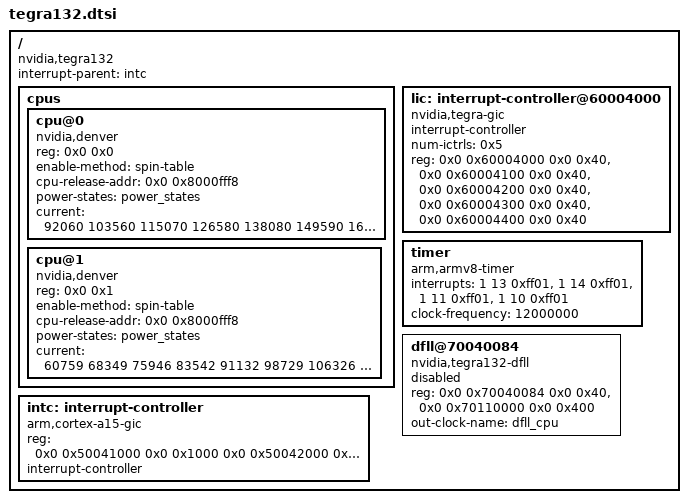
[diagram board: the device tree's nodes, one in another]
#include <dt-bindings/gpio/tegra-gpio.h>
#include <dt-bindings/input/input.h>
#include <dt-bindings/interrupt-controller/arm-gic.h>

/include/ "denver.dtsi"
/include/ "tegra124-soc.dtsi"

/ {
	compatible = "nvidia,tegra132";
	interrupt-parent = <&intc>;
	#address-cells = <2>;
	#size-cells = <2>;

	cpus {
		#address-cells = <2>;
		#size-cells = <0>;

		cpu@0 {
			device_type = "cpu";
			compatible = "nvidia,denver", "arm,armv8";
			reg = <0x0 0x0>;
			enable-method = "spin-table";
			cpu-release-addr = <0x0 0x8000fff8>;
			power-states = <&power_states>;
			// The currents(uA) correspond to the frequencies in the
			// frequency table.
			current = < 92060 //204000 kHz
			            103560 //229500 kHz
			            115070 //255000 kHz
			            126580 //280500 kHz
			            138080 //306000 kHz
			            149590 //331500 kHz
			            161100 //357000 kHz
			            172600 //382500 kHz
			            184110 //408000 kHz
			            195620 //433500 kHz
			            207120 //459000 kHz
			            218630 //484500 kHz
			            230140 //510000 kHz
			            241640 //535500 kHz
			            253150 //561000 kHz
			            264660 //586500 kHz
			            276170 //612000 kHz
			            287670 //637500 kHz
			            299180 //663000 kHz
			            310690 //688500 kHz
			            322190 //714000 kHz
			            333700 //739500 kHz
			            345210 //765000 kHz
			            356710 //790500 kHz
			            377360 //816000 kHz
			            389150 //841500 kHz
			            400950 //867000 kHz
			            412740 //892500 kHz
			            441640 //918000 kHz
			            453910 //943500 kHz
			            466180 //969000 kHz
			            478440 //994500 kHz
			            511520 //1020000 kHz
			            587620 //1122000 kHz
			            670620 //1224000 kHz
			            761250 //1326000 kHz
			            860270 //1428000 kHz
			            968510 //1530000 kHZ
			            1086830 //1632000 kHz
			            1215570 //1734000 kHz
			            1356860 //1836000 kHz
			            1511200 //1938000 kHz
			            1570850 //2014500 kHz
			            1769650 //2091000 kHz
			            1961670 //2193000 kHz
			            2170950 //2295000 kHz
			            2398880 //2397000 kHz
			            2646910>; //2499000 kHZ
		};

		cpu@1 {
			device_type = "cpu";
			compatible = "nvidia,denver", "arm,armv8";
			reg = <0x0 0x1>;
			enable-method = "spin-table";
			cpu-release-addr = <0x0 0x8000fff8>;
			power-states = <&power_states>;
			// The currents(uA) correspond to the frequencies in the
			// frequency table.
			current = < 60759 //204000 kHz
			            68349 //229500 kHz
			            75946 //255000 kHZ
			            83542 //280500 kHz
			            91132 //306000 kHz
			            98729 //331500 kHz
			            106326 //357000 kHz
			            113916 //382500 kHz
			            121512 //408000 kHz
			            129109 //433500 kHZ
			            136699 //459000 kHz
			            144295 //484500 kHz
			            151892 //510000 kHZ
			            159482 //535500 kHz
			            167079 //561000 kHz
			            174675 //586500 kHZ
			            182272 //612000 kHz
			            189862 //637500 kHz
			            197458 //663000 kHZ
			            205055 //688500 kHZ
			            212645 //714000 kHz
			            220242 //739500 kHz
			            227838 //765000 kHz
			            235428 //790500 kHz
			            249057 //816000 kHz
			            256839 //841500 kHz
			            264627 //867000 kHz
			            272408 //892500 kHz
			            291482 //918000 kHz
			            299580 //943500 kHz
			            307678 //969000 kHz
			            315770 //994500 kHz
			            337603 //1020000 kHz
			            387829 //1122000 kHz
			            442609 //1224000 kHz
			            502425 //1326000 kHz
			            567778 //1428000 kHz
			            639216 //1530000 kHz
			            717307 //1632000 kHz
			            802276 //1734000 kHz
			            895527 //1836000 kHz
			            997392 //1938000 kHz
			            1036761 //2014500 kHz
			            1167969 //2091000 kHz
			            1294702 //2193000 kHz
			            1432827 //2295000 kHz
			            1583260 //2397000 kHz
			            1746960>; //2499000 kHz

		};
	};

	intc: interrupt-controller {
		compatible = "arm,cortex-a15-gic";
		reg = <0x0 0x50041000 0x0 0x1000
		       0x0 0x50042000 0x0 0x0100>;
		interrupt-controller;
		#interrupt-cells = <3>;
	};

	lic: interrupt-controller@60004000 {
		compatible = "nvidia,tegra-gic";
		interrupt-controller;
		num-ictrls = <0x5>;
		reg = <0x0 0x60004000 0x0 0x40>,
		      <0x0 0x60004100 0x0 0x40>,
		      <0x0 0x60004200 0x0 0x40>,
		      <0x0 0x60004300 0x0 0x40>,
		      <0x0 0x60004400 0x0 0x40>;
	};

	timer {
		compatible = "arm,armv8-timer";
		interrupts = <1 13 0xff01>,
			     <1 14 0xff01>,
			     <1 11 0xff01>,
			     <1 10 0xff01>;
		clock-frequency = <12000000>;
	};

	dfll@70040084 {
		compatible = "nvidia,tegra132-dfll";
		reg = <0x0 0x70040084 0x0 0x40>,
		      <0x0 0x70110000 0x0 0x400>;
		out-clock-name="dfll_cpu";
		status = "disabled";
	};
};
